# CTRL_MODULE_CORE register map
Vendor: Texas Instruments
Registers are 32-bit, access per field, reset 0x0 unless marked. A register's access mark holds for its fields unless they carry their own. Offsets are as the file gives them; [hi:lo] are bit positions; 'fields as' and 'values as' point back to an identical list.

## CTRL_MODULE_CORE (part 11 of 12)
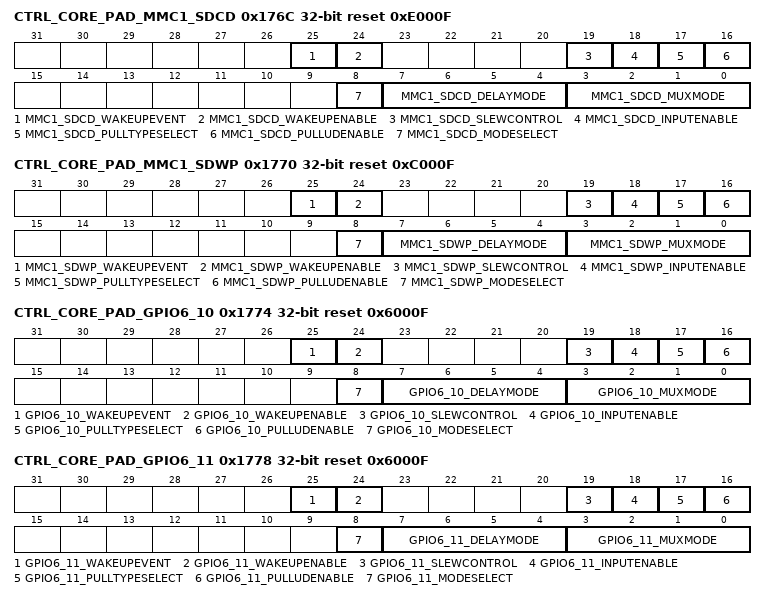
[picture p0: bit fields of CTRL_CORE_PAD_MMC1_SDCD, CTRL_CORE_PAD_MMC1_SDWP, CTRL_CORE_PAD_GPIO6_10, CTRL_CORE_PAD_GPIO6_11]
0x176C CTRL_CORE_PAD_MMC1_SDCD reset 0xE000F
  [25] MMC1_SDCD_WAKEUPEVENT ro
    0=NOWAKEUP (No wakeup event detected); 1=WAKEUP (Wakeup event detected)
  [24] MMC1_SDCD_WAKEUPENABLE rw
    0=DISABLE (Wakeup is disabled); 1=ENABLE (Wakeup is enabled)
  [19] MMC1_SDCD_SLEWCONTROL rw
    0=FAST_SLEW (Fast slew is selected); 1=SLOW_SLEW (Slow slew is selected)
  [18] MMC1_SDCD_INPUTENABLE rw
    0=DISABLE (Receive mode is disabled); 1=ENABLE (Receive mode is enabled)
  [17] MMC1_SDCD_PULLTYPESELECT rw
    0=PULL_DOWN (Pull Down is selected); 1=PULL_UP (Pull Up is selected)
  [16] MMC1_SDCD_PULLUDENABLE rw
    0=ENABLE (Enables weak Pull Up/Down); 1=DISABLE (Disables weak Pull Up/Down)
  [8] MMC1_SDCD_MODESELECT rw — Selects between the Default IO Timing Mode and a Virtual or Manual IO Timing Mode. Refer to the device Data Manual for definition of the required settings for a given mode of operation. When this bit is 0b1, a Virtual IO Timing Mode can be selected via the DELAYMODE field of this register, as described in, Virtual IO Timing Modes. Manual IO Timing Modes are selected via the procedure described in , Manual IO Timing Modes.
    0=MUX_MODE (Default IO Timing Mode is used); 1=DELAY_MODE (A Virtual or Manual IO Timing Mode is used)
  [7:4] MMC1_SDCD_DELAYMODE rw — This bit field selects the Virtual Timing Mode used when the MODESELECT bit is set to 0b1. See, Virtual IO Timing Modes for details.
  [3:0] MMC1_SDCD_MUXMODE rw
    0=MMC1_SDCD; 3=UART6_RXD; 4=I2C4_SDA; 14=GPIO6_27; 15=DRIVER OFF
0x1770 CTRL_CORE_PAD_MMC1_SDWP reset 0xC000F
  [25] MMC1_SDWP_WAKEUPEVENT ro
    values as CTRL_CORE_PAD_MMC1_SDCD.MMC1_SDCD_WAKEUPEVENT
  [24] MMC1_SDWP_WAKEUPENABLE rw
    0=DISABLE (Wakeup is disabled); 1=ENABLE (Wakeup is enabled)
  [19] MMC1_SDWP_SLEWCONTROL rw
    values as CTRL_CORE_PAD_MMC1_SDCD.MMC1_SDCD_SLEWCONTROL
  [18] MMC1_SDWP_INPUTENABLE rw
    values as CTRL_CORE_PAD_MMC1_SDCD.MMC1_SDCD_INPUTENABLE
  [17] MMC1_SDWP_PULLTYPESELECT rw
    values as CTRL_CORE_PAD_MMC1_SDCD.MMC1_SDCD_PULLTYPESELECT
  [16] MMC1_SDWP_PULLUDENABLE rw
    values as CTRL_CORE_PAD_MMC1_SDCD.MMC1_SDCD_PULLUDENABLE
  [8] MMC1_SDWP_MODESELECT rw — Selects between the Default IO Timing Mode and a Virtual or Manual IO Timing Mode. Refer to the device Data Manual for definition of the required settings for a given mode of operation. When this bit is 0b1, a Virtual IO Timing Mode can be selected via the DELAYMODE field of this register, as described in, Virtual IO Timing Modes. Manual IO Timing Modes are selected via the procedure described in , Manual IO Timing Modes.
    values as CTRL_CORE_PAD_MMC1_SDCD.MMC1_SDCD_MODESELECT
  [7:4] MMC1_SDWP_DELAYMODE rw — This bit field selects the Virtual Timing Mode used when the MODESELECT bit is set to 0b1. See, Virtual IO Timing Modes for details.
  [3:0] MMC1_SDWP_MUXMODE rw
    0=MMC1_SDWP; 3=UART6_TXD; 4=I2C4_SCL; 14=GPIO6_28; 15=DRIVER OFF
0x1774 CTRL_CORE_PAD_GPIO6_10 reset 0x6000F
  [25] GPIO6_10_WAKEUPEVENT ro
    values as CTRL_CORE_PAD_MMC1_SDCD.MMC1_SDCD_WAKEUPEVENT
  [24] GPIO6_10_WAKEUPENABLE rw
    0=DISABLE (Wakeup is disabled); 1=ENABLE (Wakeup is enabled)
  [19] GPIO6_10_SLEWCONTROL rw
    values as CTRL_CORE_PAD_MMC1_SDCD.MMC1_SDCD_SLEWCONTROL
  [18] GPIO6_10_INPUTENABLE rw
    values as CTRL_CORE_PAD_MMC1_SDCD.MMC1_SDCD_INPUTENABLE
  [17] GPIO6_10_PULLTYPESELECT rw
    values as CTRL_CORE_PAD_MMC1_SDCD.MMC1_SDCD_PULLTYPESELECT
  [16] GPIO6_10_PULLUDENABLE rw
    values as CTRL_CORE_PAD_MMC1_SDCD.MMC1_SDCD_PULLUDENABLE
  [8] GPIO6_10_MODESELECT rw — Selects between the Default IO Timing Mode and a Virtual or Manual IO Timing Mode. Refer to the device Data Manual for definition of the required settings for a given mode of operation. When this bit is 0b1, a Virtual IO Timing Mode can be selected via the DELAYMODE field of this register, as described in, Virtual IO Timing Modes. Manual IO Timing Modes are selected via the procedure described in , Manual IO Timing Modes.
    values as CTRL_CORE_PAD_MMC1_SDCD.MMC1_SDCD_MODESELECT
  [7:4] GPIO6_10_DELAYMODE rw — This bit field selects the Virtual Timing Mode used when the MODESELECT bit is set to 0b1. See, Virtual IO Timing Modes for details.
  [3:0] GPIO6_10_MUXMODE rw
    0=GPIO6_10; 1=MDIO_MCLK; 2=I2C3_SDA; 4=VIN2B_HSYNC1; 9=VIN5A_CLK0; 10=EHRPWM2A; 11=PR2_MII_MT1_CLK; 12=PR2_PRU0_GPI0; 13=PR2_PRU0_GPO0; 14=GPIO6_10; 15=DRIVER OFF
0x1778 CTRL_CORE_PAD_GPIO6_11 reset 0x6000F
  [25] GPIO6_11_WAKEUPEVENT ro
    values as CTRL_CORE_PAD_MMC1_SDCD.MMC1_SDCD_WAKEUPEVENT
  [24] GPIO6_11_WAKEUPENABLE rw
    0=DISABLE (Wakeup is disabled); 1=ENABLE (Wakeup is enabled)
  [19] GPIO6_11_SLEWCONTROL rw
    values as CTRL_CORE_PAD_MMC1_SDCD.MMC1_SDCD_SLEWCONTROL
  [18] GPIO6_11_INPUTENABLE rw
    values as CTRL_CORE_PAD_MMC1_SDCD.MMC1_SDCD_INPUTENABLE
  [17] GPIO6_11_PULLTYPESELECT rw
    values as CTRL_CORE_PAD_MMC1_SDCD.MMC1_SDCD_PULLTYPESELECT
  [16] GPIO6_11_PULLUDENABLE rw
    values as CTRL_CORE_PAD_MMC1_SDCD.MMC1_SDCD_PULLUDENABLE
  [8] GPIO6_11_MODESELECT rw — Selects between the Default IO Timing Mode and a Virtual or Manual IO Timing Mode. Refer to the device Data Manual for definition of the required settings for a given mode of operation. When this bit is 0b1, a Virtual IO Timing Mode can be selected via the DELAYMODE field of this register, as described in, Virtual IO Timing Modes. Manual IO Timing Modes are selected via the procedure described in , Manual IO Timing Modes.
    values as CTRL_CORE_PAD_MMC1_SDCD.MMC1_SDCD_MODESELECT
  [7:4] GPIO6_11_DELAYMODE rw — This bit field selects the Virtual Timing Mode used when the MODESELECT bit is set to 0b1. See, Virtual IO Timing Modes for details.
  [3:0] GPIO6_11_MUXMODE rw
    0=GPIO6_11; 1=MDIO_D; 2=I2C3_SCL; 4=VIN2B_VSYNC1; 9=VIN5A_DE0; 10=EHRPWM2B; 11=PR2_MII1_TXEN; 12=PR2_PRU0_GPI1; 13=PR2_PRU0_GPO1; 14=GPIO6_11; 15=DRIVER OFF
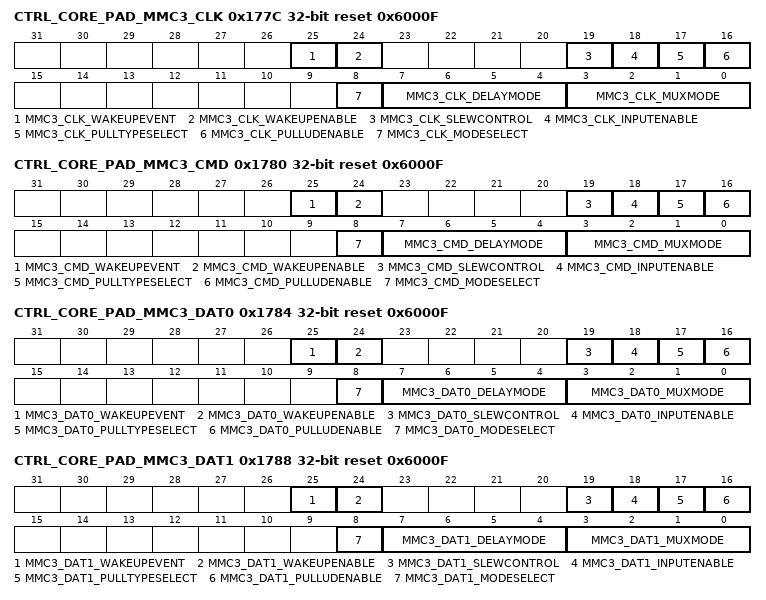
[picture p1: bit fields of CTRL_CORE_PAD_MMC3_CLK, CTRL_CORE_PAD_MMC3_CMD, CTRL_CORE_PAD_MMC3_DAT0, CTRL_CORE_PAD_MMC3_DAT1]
0x177C CTRL_CORE_PAD_MMC3_CLK reset 0x6000F
  [25] MMC3_CLK_WAKEUPEVENT ro
    values as CTRL_CORE_PAD_MMC1_SDCD.MMC1_SDCD_WAKEUPEVENT
  [24] MMC3_CLK_WAKEUPENABLE rw
    0=DISABLE (Wakeup is disabled); 1=ENABLE (Wakeup is enabled)
  [19] MMC3_CLK_SLEWCONTROL rw
    values as CTRL_CORE_PAD_MMC1_SDCD.MMC1_SDCD_SLEWCONTROL
  [18] MMC3_CLK_INPUTENABLE rw
    values as CTRL_CORE_PAD_MMC1_SDCD.MMC1_SDCD_INPUTENABLE
  [17] MMC3_CLK_PULLTYPESELECT rw
    values as CTRL_CORE_PAD_MMC1_SDCD.MMC1_SDCD_PULLTYPESELECT
  [16] MMC3_CLK_PULLUDENABLE rw
    values as CTRL_CORE_PAD_MMC1_SDCD.MMC1_SDCD_PULLUDENABLE
  [8] MMC3_CLK_MODESELECT rw — Selects between the Default IO Timing Mode and a Virtual or Manual IO Timing Mode. Refer to the device Data Manual for definition of the required settings for a given mode of operation. When this bit is 0b1, a Virtual IO Timing Mode can be selected via the DELAYMODE field of this register, as described in, Virtual IO Timing Modes. Manual IO Timing Modes are selected via the procedure described in , Manual IO Timing Modes.
    values as CTRL_CORE_PAD_MMC1_SDCD.MMC1_SDCD_MODESELECT
  [7:4] MMC3_CLK_DELAYMODE rw — This bit field selects the Virtual Timing Mode used when the MODESELECT bit is set to 0b1. See, Virtual IO Timing Modes for details.
  [3:0] MMC3_CLK_MUXMODE rw
    0=MMC3_CLK; 4=VIN2B_D7; 9=VIN5A_D7; 10=EHRPWM2_TRIPZONE_INPUT; 11=PR2_MII1_TXD3; 12=PR2_PRU0_GPI2; 13=PR2_PRU0_GPO2; 14=GPIO6_29; 15=DRIVER OFF
0x1780 CTRL_CORE_PAD_MMC3_CMD reset 0x6000F
  [25] MMC3_CMD_WAKEUPEVENT ro
    values as CTRL_CORE_PAD_MMC1_SDCD.MMC1_SDCD_WAKEUPEVENT
  [24] MMC3_CMD_WAKEUPENABLE rw
    0=DISABLE (Wakeup is disabled); 1=ENABLE (Wakeup is enabled)
  [19] MMC3_CMD_SLEWCONTROL rw
    values as CTRL_CORE_PAD_MMC1_SDCD.MMC1_SDCD_SLEWCONTROL
  [18] MMC3_CMD_INPUTENABLE rw
    values as CTRL_CORE_PAD_MMC1_SDCD.MMC1_SDCD_INPUTENABLE
  [17] MMC3_CMD_PULLTYPESELECT rw
    values as CTRL_CORE_PAD_MMC1_SDCD.MMC1_SDCD_PULLTYPESELECT
  [16] MMC3_CMD_PULLUDENABLE rw
    values as CTRL_CORE_PAD_MMC1_SDCD.MMC1_SDCD_PULLUDENABLE
  [8] MMC3_CMD_MODESELECT rw — Selects between the Default IO Timing Mode and a Virtual or Manual IO Timing Mode. Refer to the device Data Manual for definition of the required settings for a given mode of operation. When this bit is 0b1, a Virtual IO Timing Mode can be selected via the DELAYMODE field of this register, as described in, Virtual IO Timing Modes. Manual IO Timing Modes are selected via the procedure described in , Manual IO Timing Modes.
    values as CTRL_CORE_PAD_MMC1_SDCD.MMC1_SDCD_MODESELECT
  [7:4] MMC3_CMD_DELAYMODE rw — This bit field selects the Virtual Timing Mode used when the MODESELECT bit is set to 0b1. See, Virtual IO Timing Modes for details.
  [3:0] MMC3_CMD_MUXMODE rw
    0=MMC3_CMD; 1=SPI3_SCLK; 4=VIN2B_D6; 9=VIN5A_D6; 10=ECAP2_IN_PWM2_OUT; 11=PR2_MII1_TXD2; 12=PR2_PRU0_GPI3; 13=PR2_PRU0_GPO3; 14=GPIO6_30; 15=DRIVER OFF
0x1784 CTRL_CORE_PAD_MMC3_DAT0 reset 0x6000F
  [25] MMC3_DAT0_WAKEUPEVENT ro
    values as CTRL_CORE_PAD_MMC1_SDCD.MMC1_SDCD_WAKEUPEVENT
  [24] MMC3_DAT0_WAKEUPENABLE rw
    0=DISABLE (Wakeup is disabled); 1=ENABLE (Wakeup is enabled)
  [19] MMC3_DAT0_SLEWCONTROL rw
    values as CTRL_CORE_PAD_MMC1_SDCD.MMC1_SDCD_SLEWCONTROL
  [18] MMC3_DAT0_INPUTENABLE rw
    values as CTRL_CORE_PAD_MMC1_SDCD.MMC1_SDCD_INPUTENABLE
  [17] MMC3_DAT0_PULLTYPESELECT rw
    values as CTRL_CORE_PAD_MMC1_SDCD.MMC1_SDCD_PULLTYPESELECT
  [16] MMC3_DAT0_PULLUDENABLE rw
    values as CTRL_CORE_PAD_MMC1_SDCD.MMC1_SDCD_PULLUDENABLE
  [8] MMC3_DAT0_MODESELECT rw — Selects between the Default IO Timing Mode and a Virtual or Manual IO Timing Mode. Refer to the device Data Manual for definition of the required settings for a given mode of operation. When this bit is 0b1, a Virtual IO Timing Mode can be selected via the DELAYMODE field of this register, as described in, Virtual IO Timing Modes. Manual IO Timing Modes are selected via the procedure described in , Manual IO Timing Modes.
    values as CTRL_CORE_PAD_MMC1_SDCD.MMC1_SDCD_MODESELECT
  [7:4] MMC3_DAT0_DELAYMODE rw — This bit field selects the Virtual Timing Mode used when the MODESELECT bit is set to 0b1. See, Virtual IO Timing Modes for details.
  [3:0] MMC3_DAT0_MUXMODE rw
    0=MMC3_DAT0; 1=SPI3_D1; 2=UART5_RXD; 4=VIN2B_D5; 9=VIN5A_D5; 10=EQEP3A_IN; 11=PR2_MII1_TXD1; 12=PR2_PRU0_GPI4; 13=PR2_PRU0_GPO4; 14=GPIO6_31; 15=DRIVER OFF
0x1788 CTRL_CORE_PAD_MMC3_DAT1 reset 0x6000F
  [25] MMC3_DAT1_WAKEUPEVENT ro
    values as CTRL_CORE_PAD_MMC1_SDCD.MMC1_SDCD_WAKEUPEVENT
  [24] MMC3_DAT1_WAKEUPENABLE rw
    0=DISABLE (Wakeup is disabled); 1=ENABLE (Wakeup is enabled)
  [19] MMC3_DAT1_SLEWCONTROL rw
    values as CTRL_CORE_PAD_MMC1_SDCD.MMC1_SDCD_SLEWCONTROL
  [18] MMC3_DAT1_INPUTENABLE rw
    values as CTRL_CORE_PAD_MMC1_SDCD.MMC1_SDCD_INPUTENABLE
  [17] MMC3_DAT1_PULLTYPESELECT rw
    values as CTRL_CORE_PAD_MMC1_SDCD.MMC1_SDCD_PULLTYPESELECT
  [16] MMC3_DAT1_PULLUDENABLE rw
    values as CTRL_CORE_PAD_MMC1_SDCD.MMC1_SDCD_PULLUDENABLE
  [8] MMC3_DAT1_MODESELECT rw — Selects between the Default IO Timing Mode and a Virtual or Manual IO Timing Mode. Refer to the device Data Manual for definition of the required settings for a given mode of operation. When this bit is 0b1, a Virtual IO Timing Mode can be selected via the DELAYMODE field of this register, as described in, Virtual IO Timing Modes. Manual IO Timing Modes are selected via the procedure described in , Manual IO Timing Modes.
    values as CTRL_CORE_PAD_MMC1_SDCD.MMC1_SDCD_MODESELECT
  [7:4] MMC3_DAT1_DELAYMODE rw — This bit field selects the Virtual Timing Mode used when the MODESELECT bit is set to 0b1. See, Virtual IO Timing Modes for details.
  [3:0] MMC3_DAT1_MUXMODE rw
    0=MMC3_DAT1; 1=SPI3_D0; 2=UART5_TXD; 4=VIN2B_D4; 9=VIN5A_D4; 10=EQEP3B_IN; 11=PR2_MII1_TXD0; 12=PR2_PRU0_GPI5; 13=PR2_PRU0_GPO5; 14=GPIO7_0; 15=DRIVER OFF
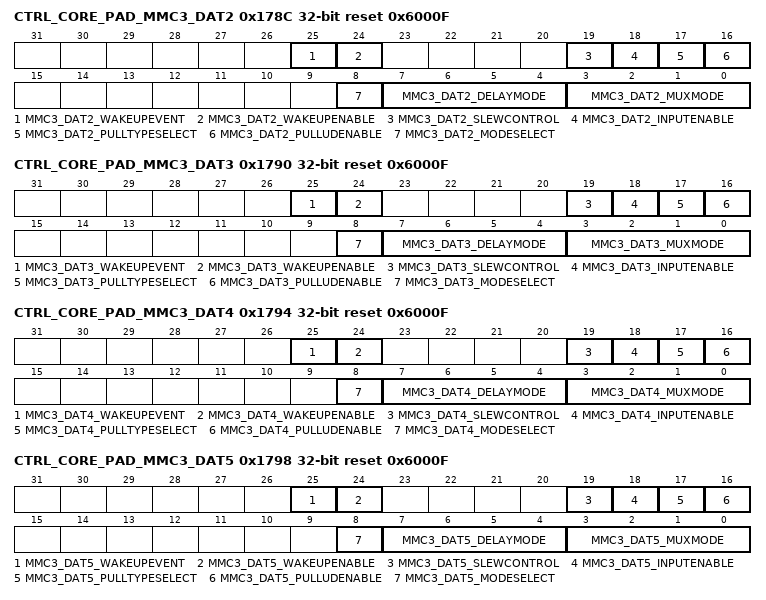
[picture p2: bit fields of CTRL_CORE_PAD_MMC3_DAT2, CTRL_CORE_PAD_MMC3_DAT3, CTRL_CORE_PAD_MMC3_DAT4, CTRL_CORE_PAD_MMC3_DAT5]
0x178C CTRL_CORE_PAD_MMC3_DAT2 reset 0x6000F
  [25] MMC3_DAT2_WAKEUPEVENT ro
    values as CTRL_CORE_PAD_MMC1_SDCD.MMC1_SDCD_WAKEUPEVENT
  [24] MMC3_DAT2_WAKEUPENABLE rw
    0=DISABLE (Wakeup is disabled); 1=ENABLE (Wakeup is enabled)
  [19] MMC3_DAT2_SLEWCONTROL rw
    values as CTRL_CORE_PAD_MMC1_SDCD.MMC1_SDCD_SLEWCONTROL
  [18] MMC3_DAT2_INPUTENABLE rw
    values as CTRL_CORE_PAD_MMC1_SDCD.MMC1_SDCD_INPUTENABLE
  [17] MMC3_DAT2_PULLTYPESELECT rw
    values as CTRL_CORE_PAD_MMC1_SDCD.MMC1_SDCD_PULLTYPESELECT
  [16] MMC3_DAT2_PULLUDENABLE rw
    values as CTRL_CORE_PAD_MMC1_SDCD.MMC1_SDCD_PULLUDENABLE
  [8] MMC3_DAT2_MODESELECT rw — Selects between the Default IO Timing Mode and a Virtual or Manual IO Timing Mode. Refer to the device Data Manual for definition of the required settings for a given mode of operation. When this bit is 0b1, a Virtual IO Timing Mode can be selected via the DELAYMODE field of this register, as described in, Virtual IO Timing Modes. Manual IO Timing Modes are selected via the procedure described in , Manual IO Timing Modes.
    values as CTRL_CORE_PAD_MMC1_SDCD.MMC1_SDCD_MODESELECT
  [7:4] MMC3_DAT2_DELAYMODE rw — This bit field selects the Virtual Timing Mode used when the MODESELECT bit is set to 0b1. See, Virtual IO Timing Modes for details.
  [3:0] MMC3_DAT2_MUXMODE rw
    0=MMC3_DAT2; 1=SPI3_CS0; 2=UART5_CTSN; 4=VIN2B_D3; 9=VIN5A_D3; 10=EQEP3_INDEX; 11=PR2_MII_MR1_CLK; 12=PR2_PRU0_GPI6; 13=PR2_PRU0_GPO6; 14=GPIO7_1; 15=DRIVER OFF
0x1790 CTRL_CORE_PAD_MMC3_DAT3 reset 0x6000F
  [25] MMC3_DAT3_WAKEUPEVENT ro
    values as CTRL_CORE_PAD_MMC1_SDCD.MMC1_SDCD_WAKEUPEVENT
  [24] MMC3_DAT3_WAKEUPENABLE rw
    0=DISABLE (Wakeup is disabled); 1=ENABLE (Wakeup is enabled)
  [19] MMC3_DAT3_SLEWCONTROL rw
    values as CTRL_CORE_PAD_MMC1_SDCD.MMC1_SDCD_SLEWCONTROL
  [18] MMC3_DAT3_INPUTENABLE rw
    values as CTRL_CORE_PAD_MMC1_SDCD.MMC1_SDCD_INPUTENABLE
  [17] MMC3_DAT3_PULLTYPESELECT rw
    values as CTRL_CORE_PAD_MMC1_SDCD.MMC1_SDCD_PULLTYPESELECT
  [16] MMC3_DAT3_PULLUDENABLE rw
    values as CTRL_CORE_PAD_MMC1_SDCD.MMC1_SDCD_PULLUDENABLE
  [8] MMC3_DAT3_MODESELECT rw — Selects between the Default IO Timing Mode and a Virtual or Manual IO Timing Mode. Refer to the device Data Manual for definition of the required settings for a given mode of operation. When this bit is 0b1, a Virtual IO Timing Mode can be selected via the DELAYMODE field of this register, as described in, Virtual IO Timing Modes. Manual IO Timing Modes are selected via the procedure described in , Manual IO Timing Modes.
    values as CTRL_CORE_PAD_MMC1_SDCD.MMC1_SDCD_MODESELECT
  [7:4] MMC3_DAT3_DELAYMODE rw — This bit field selects the Virtual Timing Mode used when the MODESELECT bit is set to 0b1. See, Virtual IO Timing Modes for details.
  [3:0] MMC3_DAT3_MUXMODE rw
    0=MMC3_DAT3; 1=SPI3_CS1; 2=UART5_RTSN; 4=VIN2B_D2; 9=VIN5A_D2; 10=EQEP3_STROBE; 11=PR2_MII1_RXDV; 12=PR2_PRU0_GPI7; 13=PR2_PRU0_GPO7; 14=GPIO7_2; 15=DRIVER OFF
0x1794 CTRL_CORE_PAD_MMC3_DAT4 reset 0x6000F
  [25] MMC3_DAT4_WAKEUPEVENT ro
    values as CTRL_CORE_PAD_MMC1_SDCD.MMC1_SDCD_WAKEUPEVENT
  [24] MMC3_DAT4_WAKEUPENABLE rw
    0=DISABLE (Wakeup is disabled); 1=ENABLE (Wakeup is enabled)
  [19] MMC3_DAT4_SLEWCONTROL rw
    values as CTRL_CORE_PAD_MMC1_SDCD.MMC1_SDCD_SLEWCONTROL
  [18] MMC3_DAT4_INPUTENABLE rw
    values as CTRL_CORE_PAD_MMC1_SDCD.MMC1_SDCD_INPUTENABLE
  [17] MMC3_DAT4_PULLTYPESELECT rw
    values as CTRL_CORE_PAD_MMC1_SDCD.MMC1_SDCD_PULLTYPESELECT
  [16] MMC3_DAT4_PULLUDENABLE rw
    values as CTRL_CORE_PAD_MMC1_SDCD.MMC1_SDCD_PULLUDENABLE
  [8] MMC3_DAT4_MODESELECT rw — Selects between the Default IO Timing Mode and a Virtual or Manual IO Timing Mode. Refer to the device Data Manual for definition of the required settings for a given mode of operation. When this bit is 0b1, a Virtual IO Timing Mode can be selected via the DELAYMODE field of this register, as described in, Virtual IO Timing Modes. Manual IO Timing Modes are selected via the procedure described in , Manual IO Timing Modes.
    values as CTRL_CORE_PAD_MMC1_SDCD.MMC1_SDCD_MODESELECT
  [7:4] MMC3_DAT4_DELAYMODE rw — This bit field selects the Virtual Timing Mode used when the MODESELECT bit is set to 0b1. See, Virtual IO Timing Modes for details.
  [3:0] MMC3_DAT4_MUXMODE rw
    0=MMC3_DAT4; 1=SPI4_SCLK; 2=UART10_RXD; 4=VIN2B_D1; 9=VIN5A_D1; 10=EHRPWM3A; 11=PR2_MII1_RXD3; 12=PR2_PRU0_GPI8; 13=PR2_PRU0_GPO8; 14=GPIO1_22; 15=DRIVER OFF
0x1798 CTRL_CORE_PAD_MMC3_DAT5 reset 0x6000F
  [25] MMC3_DAT5_WAKEUPEVENT ro
    values as CTRL_CORE_PAD_MMC1_SDCD.MMC1_SDCD_WAKEUPEVENT
  [24] MMC3_DAT5_WAKEUPENABLE rw
    0=DISABLE (Wakeup is disabled); 1=ENABLE (Wakeup is enabled)
  [19] MMC3_DAT5_SLEWCONTROL rw
    values as CTRL_CORE_PAD_MMC1_SDCD.MMC1_SDCD_SLEWCONTROL
  [18] MMC3_DAT5_INPUTENABLE rw
    values as CTRL_CORE_PAD_MMC1_SDCD.MMC1_SDCD_INPUTENABLE
  [17] MMC3_DAT5_PULLTYPESELECT rw
    values as CTRL_CORE_PAD_MMC1_SDCD.MMC1_SDCD_PULLTYPESELECT
  [16] MMC3_DAT5_PULLUDENABLE rw
    values as CTRL_CORE_PAD_MMC1_SDCD.MMC1_SDCD_PULLUDENABLE
  [8] MMC3_DAT5_MODESELECT rw — Selects between the Default IO Timing Mode and a Virtual or Manual IO Timing Mode. Refer to the device Data Manual for definition of the required settings for a given mode of operation. When this bit is 0b1, a Virtual IO Timing Mode can be selected via the DELAYMODE field of this register, as described in, Virtual IO Timing Modes. Manual IO Timing Modes are selected via the procedure described in , Manual IO Timing Modes.
    values as CTRL_CORE_PAD_MMC1_SDCD.MMC1_SDCD_MODESELECT
  [7:4] MMC3_DAT5_DELAYMODE rw — This bit field selects the Virtual Timing Mode used when the MODESELECT bit is set to 0b1. See, Virtual IO Timing Modes for details.
  [3:0] MMC3_DAT5_MUXMODE rw
    0=MMC3_DAT5; 1=SPI4_D1; 2=UART10_TXD; 4=VIN2B_D0; 9=VIN5A_D0; 10=EHRPWM3B; 11=PR2_MII1_RXD2; 12=PR2_PRU0_GPI9; 13=PR2_PRU0_GPO9; 14=GPIO1_23; 15=DRIVER OFF
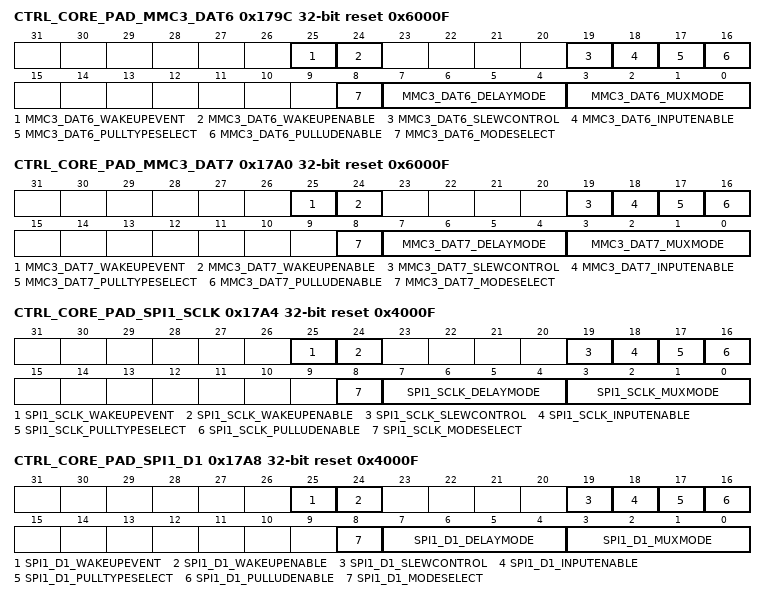
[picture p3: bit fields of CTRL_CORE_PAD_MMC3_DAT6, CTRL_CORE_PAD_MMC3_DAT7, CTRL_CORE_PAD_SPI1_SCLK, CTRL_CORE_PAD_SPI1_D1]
0x179C CTRL_CORE_PAD_MMC3_DAT6 reset 0x6000F
  [25] MMC3_DAT6_WAKEUPEVENT ro
    values as CTRL_CORE_PAD_MMC1_SDCD.MMC1_SDCD_WAKEUPEVENT
  [24] MMC3_DAT6_WAKEUPENABLE rw
    0=DISABLE (Wakeup is disabled); 1=ENABLE (Wakeup is enabled)
  [19] MMC3_DAT6_SLEWCONTROL rw
    values as CTRL_CORE_PAD_MMC1_SDCD.MMC1_SDCD_SLEWCONTROL
  [18] MMC3_DAT6_INPUTENABLE rw
    values as CTRL_CORE_PAD_MMC1_SDCD.MMC1_SDCD_INPUTENABLE
  [17] MMC3_DAT6_PULLTYPESELECT rw
    values as CTRL_CORE_PAD_MMC1_SDCD.MMC1_SDCD_PULLTYPESELECT
  [16] MMC3_DAT6_PULLUDENABLE rw
    values as CTRL_CORE_PAD_MMC1_SDCD.MMC1_SDCD_PULLUDENABLE
  [8] MMC3_DAT6_MODESELECT rw — Selects between the Default IO Timing Mode and a Virtual or Manual IO Timing Mode. Refer to the device Data Manual for definition of the required settings for a given mode of operation. When this bit is 0b1, a Virtual IO Timing Mode can be selected via the DELAYMODE field of this register, as described in, Virtual IO Timing Modes. Manual IO Timing Modes are selected via the procedure described in , Manual IO Timing Modes.
    values as CTRL_CORE_PAD_MMC1_SDCD.MMC1_SDCD_MODESELECT
  [7:4] MMC3_DAT6_DELAYMODE rw — This bit field selects the Virtual Timing Mode used when the MODESELECT bit is set to 0b1. See, Virtual IO Timing Modes for details.
  [3:0] MMC3_DAT6_MUXMODE rw
    0=MMC3_DAT6; 1=SPI4_D0; 2=UART10_CTSN; 4=VIN2B_DE1; 9=VIN5A_HSYNC0; 10=EHRPWM3_TRIPZONE_INPUT; 11=PR2_MII1_RXD1; 12=PR2_PRU0_GPI10; 13=PR2_PRU0_GPO10; 14=GPIO1_24; 15=DRIVER OFF
0x17A0 CTRL_CORE_PAD_MMC3_DAT7 reset 0x6000F
  [25] MMC3_DAT7_WAKEUPEVENT ro
    values as CTRL_CORE_PAD_MMC1_SDCD.MMC1_SDCD_WAKEUPEVENT
  [24] MMC3_DAT7_WAKEUPENABLE rw
    0=DISABLE (Wakeup is disabled); 1=ENABLE (Wakeup is enabled)
  [19] MMC3_DAT7_SLEWCONTROL rw
    values as CTRL_CORE_PAD_MMC1_SDCD.MMC1_SDCD_SLEWCONTROL
  [18] MMC3_DAT7_INPUTENABLE rw
    values as CTRL_CORE_PAD_MMC1_SDCD.MMC1_SDCD_INPUTENABLE
  [17] MMC3_DAT7_PULLTYPESELECT rw
    values as CTRL_CORE_PAD_MMC1_SDCD.MMC1_SDCD_PULLTYPESELECT
  [16] MMC3_DAT7_PULLUDENABLE rw
    values as CTRL_CORE_PAD_MMC1_SDCD.MMC1_SDCD_PULLUDENABLE
  [8] MMC3_DAT7_MODESELECT rw — Selects between the Default IO Timing Mode and a Virtual or Manual IO Timing Mode. Refer to the device Data Manual for definition of the required settings for a given mode of operation. When this bit is 0b1, a Virtual IO Timing Mode can be selected via the DELAYMODE field of this register, as described in, Virtual IO Timing Modes. Manual IO Timing Modes are selected via the procedure described in , Manual IO Timing Modes.
    values as CTRL_CORE_PAD_MMC1_SDCD.MMC1_SDCD_MODESELECT
  [7:4] MMC3_DAT7_DELAYMODE rw — This bit field selects the Virtual Timing Mode used when the MODESELECT bit is set to 0b1. See, Virtual IO Timing Modes for details.
  [3:0] MMC3_DAT7_MUXMODE rw
    0=MMC3_DAT7; 1=SPI4_CS0; 2=UART10_RTSN; 4=VIN2B_CLK1; 9=VIN5A_VSYNC0; 10=ECAP3_IN_PWM3_OUT; 11=PR2_MII1_RXD0; 12=PR2_PRU0_GPI11; 13=PR2_PRU0_GPO11; 14=GPIO1_25; 15=DRIVER OFF
0x17A4 CTRL_CORE_PAD_SPI1_SCLK reset 0x4000F
  [25] SPI1_SCLK_WAKEUPEVENT ro
    values as CTRL_CORE_PAD_MMC1_SDCD.MMC1_SDCD_WAKEUPEVENT
  [24] SPI1_SCLK_WAKEUPENABLE rw
    0=DISABLE (Wakeup is disabled); 1=ENABLE (Wakeup is enabled)
  [19] SPI1_SCLK_SLEWCONTROL rw
    values as CTRL_CORE_PAD_MMC1_SDCD.MMC1_SDCD_SLEWCONTROL
  [18] SPI1_SCLK_INPUTENABLE rw
    values as CTRL_CORE_PAD_MMC1_SDCD.MMC1_SDCD_INPUTENABLE
  [17] SPI1_SCLK_PULLTYPESELECT rw
    values as CTRL_CORE_PAD_MMC1_SDCD.MMC1_SDCD_PULLTYPESELECT
  [16] SPI1_SCLK_PULLUDENABLE rw
    values as CTRL_CORE_PAD_MMC1_SDCD.MMC1_SDCD_PULLUDENABLE
  [8] SPI1_SCLK_MODESELECT rw — Selects between the Default IO Timing Mode and a Virtual or Manual IO Timing Mode. Refer to the device Data Manual for definition of the required settings for a given mode of operation. When this bit is 0b1, a Virtual IO Timing Mode can be selected via the DELAYMODE field of this register, as described in, Virtual IO Timing Modes. Manual IO Timing Modes are selected via the procedure described in , Manual IO Timing Modes.
    values as CTRL_CORE_PAD_MMC1_SDCD.MMC1_SDCD_MODESELECT
  [7:4] SPI1_SCLK_DELAYMODE rw — This bit field selects the Virtual Timing Mode used when the MODESELECT bit is set to 0b1. See, Virtual IO Timing Modes for details.
  [3:0] SPI1_SCLK_MUXMODE rw
    0=SPI1_SCLK; 14=GPIO7_7; 15=DRIVER OFF
0x17A8 CTRL_CORE_PAD_SPI1_D1 reset 0x4000F
  [25] SPI1_D1_WAKEUPEVENT ro
    values as CTRL_CORE_PAD_MMC1_SDCD.MMC1_SDCD_WAKEUPEVENT
  [24] SPI1_D1_WAKEUPENABLE rw
    0=DISABLE (Wakeup is disabled); 1=ENABLE (Wakeup is enabled)
  [19] SPI1_D1_SLEWCONTROL rw
    values as CTRL_CORE_PAD_MMC1_SDCD.MMC1_SDCD_SLEWCONTROL
  [18] SPI1_D1_INPUTENABLE rw
    values as CTRL_CORE_PAD_MMC1_SDCD.MMC1_SDCD_INPUTENABLE
  [17] SPI1_D1_PULLTYPESELECT rw
    values as CTRL_CORE_PAD_MMC1_SDCD.MMC1_SDCD_PULLTYPESELECT
  [16] SPI1_D1_PULLUDENABLE rw
    values as CTRL_CORE_PAD_MMC1_SDCD.MMC1_SDCD_PULLUDENABLE
  [8] SPI1_D1_MODESELECT rw — Selects between the Default IO Timing Mode and a Virtual or Manual IO Timing Mode. Refer to the device Data Manual for definition of the required settings for a given mode of operation. When this bit is 0b1, a Virtual IO Timing Mode can be selected via the DELAYMODE field of this register, as described in, Virtual IO Timing Modes. Manual IO Timing Modes are selected via the procedure described in , Manual IO Timing Modes.
    values as CTRL_CORE_PAD_MMC1_SDCD.MMC1_SDCD_MODESELECT
  [7:4] SPI1_D1_DELAYMODE rw — This bit field selects the Virtual Timing Mode used when the MODESELECT bit is set to 0b1. See, Virtual IO Timing Modes for details.
  [3:0] SPI1_D1_MUXMODE rw
    0=SPI1_D1; 14=GPIO7_8; 15=DRIVER OFF
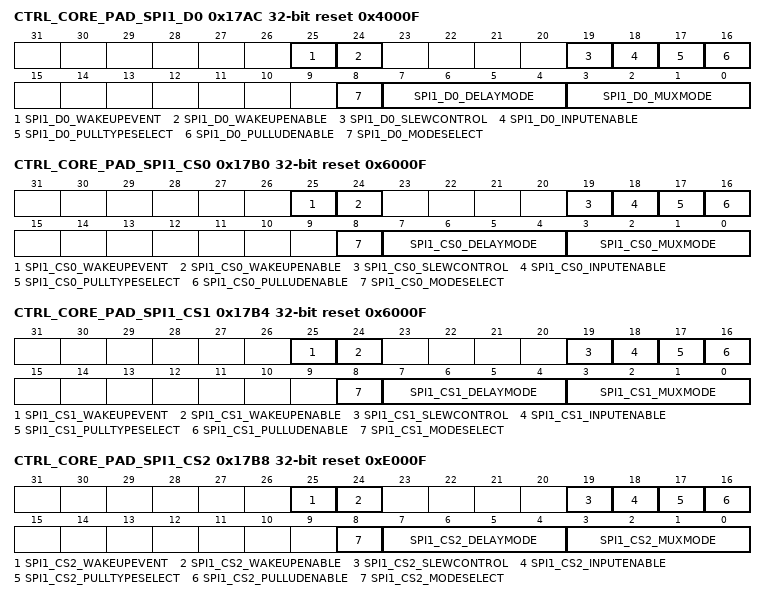
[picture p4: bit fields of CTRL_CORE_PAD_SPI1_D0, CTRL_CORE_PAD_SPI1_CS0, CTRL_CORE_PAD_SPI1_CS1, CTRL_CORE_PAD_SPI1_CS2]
0x17AC CTRL_CORE_PAD_SPI1_D0 reset 0x4000F
  [25] SPI1_D0_WAKEUPEVENT ro
    values as CTRL_CORE_PAD_MMC1_SDCD.MMC1_SDCD_WAKEUPEVENT
  [24] SPI1_D0_WAKEUPENABLE rw
    0=DISABLE (Wakeup is disabled); 1=ENABLE (Wakeup is enabled)
  [19] SPI1_D0_SLEWCONTROL rw
    values as CTRL_CORE_PAD_MMC1_SDCD.MMC1_SDCD_SLEWCONTROL
  [18] SPI1_D0_INPUTENABLE rw
    values as CTRL_CORE_PAD_MMC1_SDCD.MMC1_SDCD_INPUTENABLE
  [17] SPI1_D0_PULLTYPESELECT rw
    values as CTRL_CORE_PAD_MMC1_SDCD.MMC1_SDCD_PULLTYPESELECT
  [16] SPI1_D0_PULLUDENABLE rw
    values as CTRL_CORE_PAD_MMC1_SDCD.MMC1_SDCD_PULLUDENABLE
  [8] SPI1_D0_MODESELECT rw — Selects between the Default IO Timing Mode and a Virtual or Manual IO Timing Mode. Refer to the device Data Manual for definition of the required settings for a given mode of operation. When this bit is 0b1, a Virtual IO Timing Mode can be selected via the DELAYMODE field of this register, as described in, Virtual IO Timing Modes. Manual IO Timing Modes are selected via the procedure described in , Manual IO Timing Modes.
    values as CTRL_CORE_PAD_MMC1_SDCD.MMC1_SDCD_MODESELECT
  [7:4] SPI1_D0_DELAYMODE rw — This bit field selects the Virtual Timing Mode used when the MODESELECT bit is set to 0b1. See, Virtual IO Timing Modes for details.
  [3:0] SPI1_D0_MUXMODE rw
    0=SPI1_D0; 14=GPIO7_9; 15=DRIVER OFF
0x17B0 CTRL_CORE_PAD_SPI1_CS0 reset 0x6000F
  [25] SPI1_CS0_WAKEUPEVENT ro
    values as CTRL_CORE_PAD_MMC1_SDCD.MMC1_SDCD_WAKEUPEVENT
  [24] SPI1_CS0_WAKEUPENABLE rw
    0=DISABLE (Wakeup is disabled); 1=ENABLE (Wakeup is enabled)
  [19] SPI1_CS0_SLEWCONTROL rw
    values as CTRL_CORE_PAD_MMC1_SDCD.MMC1_SDCD_SLEWCONTROL
  [18] SPI1_CS0_INPUTENABLE rw
    values as CTRL_CORE_PAD_MMC1_SDCD.MMC1_SDCD_INPUTENABLE
  [17] SPI1_CS0_PULLTYPESELECT rw
    values as CTRL_CORE_PAD_MMC1_SDCD.MMC1_SDCD_PULLTYPESELECT
  [16] SPI1_CS0_PULLUDENABLE rw
    values as CTRL_CORE_PAD_MMC1_SDCD.MMC1_SDCD_PULLUDENABLE
  [8] SPI1_CS0_MODESELECT rw — Selects between the Default IO Timing Mode and a Virtual or Manual IO Timing Mode. Refer to the device Data Manual for definition of the required settings for a given mode of operation. When this bit is 0b1, a Virtual IO Timing Mode can be selected via the DELAYMODE field of this register, as described in, Virtual IO Timing Modes. Manual IO Timing Modes are selected via the procedure described in , Manual IO Timing Modes.
    values as CTRL_CORE_PAD_MMC1_SDCD.MMC1_SDCD_MODESELECT
  [7:4] SPI1_CS0_DELAYMODE rw — This bit field selects the Virtual Timing Mode used when the MODESELECT bit is set to 0b1. See, Virtual IO Timing Modes for details.
  [3:0] SPI1_CS0_MUXMODE rw
    0=SPI1_CS0; 14=GPIO7_10; 15=DRIVER OFF
0x17B4 CTRL_CORE_PAD_SPI1_CS1 reset 0x6000F
  [25] SPI1_CS1_WAKEUPEVENT ro
    values as CTRL_CORE_PAD_MMC1_SDCD.MMC1_SDCD_WAKEUPEVENT
  [24] SPI1_CS1_WAKEUPENABLE rw
    0=DISABLE (Wakeup is disabled); 1=ENABLE (Wakeup is enabled)
  [19] SPI1_CS1_SLEWCONTROL rw
    values as CTRL_CORE_PAD_MMC1_SDCD.MMC1_SDCD_SLEWCONTROL
  [18] SPI1_CS1_INPUTENABLE rw
    values as CTRL_CORE_PAD_MMC1_SDCD.MMC1_SDCD_INPUTENABLE
  [17] SPI1_CS1_PULLTYPESELECT rw
    values as CTRL_CORE_PAD_MMC1_SDCD.MMC1_SDCD_PULLTYPESELECT
  [16] SPI1_CS1_PULLUDENABLE rw
    values as CTRL_CORE_PAD_MMC1_SDCD.MMC1_SDCD_PULLUDENABLE
  [8] SPI1_CS1_MODESELECT rw — Selects between the Default IO Timing Mode and a Virtual or Manual IO Timing Mode. Refer to the device Data Manual for definition of the required settings for a given mode of operation. When this bit is 0b1, a Virtual IO Timing Mode can be selected via the DELAYMODE field of this register, as described in, Virtual IO Timing Modes. Manual IO Timing Modes are selected via the procedure described in , Manual IO Timing Modes.
    values as CTRL_CORE_PAD_MMC1_SDCD.MMC1_SDCD_MODESELECT
  [7:4] SPI1_CS1_DELAYMODE rw — This bit field selects the Virtual Timing Mode used when the MODESELECT bit is set to 0b1. See, Virtual IO Timing Modes for details.
  [3:0] SPI1_CS1_MUXMODE rw
    0=SPI1_CS1; 2=SATA1_LED; 3=SPI2_CS1; 14=GPIO7_11; 15=DRIVER OFF
0x17B8 CTRL_CORE_PAD_SPI1_CS2 reset 0xE000F
  [25] SPI1_CS2_WAKEUPEVENT ro
    values as CTRL_CORE_PAD_MMC1_SDCD.MMC1_SDCD_WAKEUPEVENT
  [24] SPI1_CS2_WAKEUPENABLE rw
    0=DISABLE (Wakeup is disabled); 1=ENABLE (Wakeup is enabled)
  [19] SPI1_CS2_SLEWCONTROL rw
    values as CTRL_CORE_PAD_MMC1_SDCD.MMC1_SDCD_SLEWCONTROL
  [18] SPI1_CS2_INPUTENABLE rw
    values as CTRL_CORE_PAD_MMC1_SDCD.MMC1_SDCD_INPUTENABLE
  [17] SPI1_CS2_PULLTYPESELECT rw
    values as CTRL_CORE_PAD_MMC1_SDCD.MMC1_SDCD_PULLTYPESELECT
  [16] SPI1_CS2_PULLUDENABLE rw
    values as CTRL_CORE_PAD_MMC1_SDCD.MMC1_SDCD_PULLUDENABLE
  [8] SPI1_CS2_MODESELECT rw — Selects between the Default IO Timing Mode and a Virtual or Manual IO Timing Mode. Refer to the device Data Manual for definition of the required settings for a given mode of operation. When this bit is 0b1, a Virtual IO Timing Mode can be selected via the DELAYMODE field of this register, as described in, Virtual IO Timing Modes. Manual IO Timing Modes are selected via the procedure described in , Manual IO Timing Modes.
    values as CTRL_CORE_PAD_MMC1_SDCD.MMC1_SDCD_MODESELECT
  [7:4] SPI1_CS2_DELAYMODE rw — This bit field selects the Virtual Timing Mode used when the MODESELECT bit is set to 0b1. See, Virtual IO Timing Modes for details.
  [3:0] SPI1_CS2_MUXMODE rw
    0=SPI1_CS2; 1=UART4_RXD; 2=MMC3_SDCD; 3=SPI2_CS2; 4=DCAN2_TX; 5=MDIO_MCLK; 6=HDMI1_HPD; 14=GPIO7_12; 15=DRIVER OFF
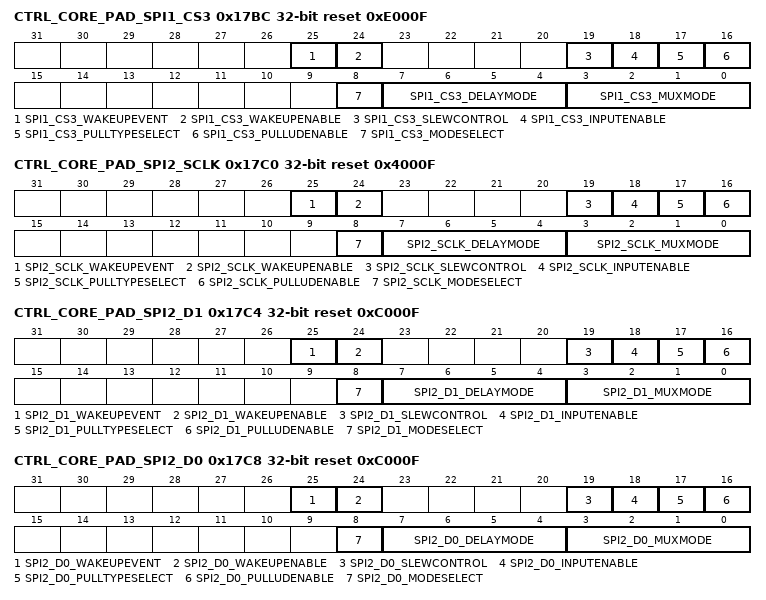
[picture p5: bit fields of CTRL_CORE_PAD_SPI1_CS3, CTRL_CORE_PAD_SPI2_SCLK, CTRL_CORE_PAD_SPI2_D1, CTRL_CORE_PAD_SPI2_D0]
0x17BC CTRL_CORE_PAD_SPI1_CS3 reset 0xE000F
  [25] SPI1_CS3_WAKEUPEVENT ro
    values as CTRL_CORE_PAD_MMC1_SDCD.MMC1_SDCD_WAKEUPEVENT
  [24] SPI1_CS3_WAKEUPENABLE rw
    0=DISABLE (Wakeup is disabled); 1=ENABLE (Wakeup is enabled)
  [19] SPI1_CS3_SLEWCONTROL rw
    values as CTRL_CORE_PAD_MMC1_SDCD.MMC1_SDCD_SLEWCONTROL
  [18] SPI1_CS3_INPUTENABLE rw
    values as CTRL_CORE_PAD_MMC1_SDCD.MMC1_SDCD_INPUTENABLE
  [17] SPI1_CS3_PULLTYPESELECT rw
    values as CTRL_CORE_PAD_MMC1_SDCD.MMC1_SDCD_PULLTYPESELECT
  [16] SPI1_CS3_PULLUDENABLE rw
    values as CTRL_CORE_PAD_MMC1_SDCD.MMC1_SDCD_PULLUDENABLE
  [8] SPI1_CS3_MODESELECT rw — Selects between the Default IO Timing Mode and a Virtual or Manual IO Timing Mode. Refer to the device Data Manual for definition of the required settings for a given mode of operation. When this bit is 0b1, a Virtual IO Timing Mode can be selected via the DELAYMODE field of this register, as described in, Virtual IO Timing Modes. Manual IO Timing Modes are selected via the procedure described in , Manual IO Timing Modes.
    values as CTRL_CORE_PAD_MMC1_SDCD.MMC1_SDCD_MODESELECT
  [7:4] SPI1_CS3_DELAYMODE rw — This bit field selects the Virtual Timing Mode used when the MODESELECT bit is set to 0b1. See, Virtual IO Timing Modes for details.
  [3:0] SPI1_CS3_MUXMODE rw
    0=SPI1_CS3; 1=UART4_TXD; 2=MMC3_SDWP; 3=SPI2_CS3; 4=DCAN2_RX; 5=MDIO_D; 6=HDMI1_CEC; 14=GPIO7_13; 15=DRIVER OFF
0x17C0 CTRL_CORE_PAD_SPI2_SCLK reset 0x4000F
  [25] SPI2_SCLK_WAKEUPEVENT ro
    values as CTRL_CORE_PAD_MMC1_SDCD.MMC1_SDCD_WAKEUPEVENT
  [24] SPI2_SCLK_WAKEUPENABLE rw
    0=DISABLE (Wakeup is disabled); 1=ENABLE (Wakeup is enabled)
  [19] SPI2_SCLK_SLEWCONTROL rw
    values as CTRL_CORE_PAD_MMC1_SDCD.MMC1_SDCD_SLEWCONTROL
  [18] SPI2_SCLK_INPUTENABLE rw
    values as CTRL_CORE_PAD_MMC1_SDCD.MMC1_SDCD_INPUTENABLE
  [17] SPI2_SCLK_PULLTYPESELECT rw
    values as CTRL_CORE_PAD_MMC1_SDCD.MMC1_SDCD_PULLTYPESELECT
  [16] SPI2_SCLK_PULLUDENABLE rw
    values as CTRL_CORE_PAD_MMC1_SDCD.MMC1_SDCD_PULLUDENABLE
  [8] SPI2_SCLK_MODESELECT rw — Selects between the Default IO Timing Mode and a Virtual or Manual IO Timing Mode. Refer to the device Data Manual for definition of the required settings for a given mode of operation. When this bit is 0b1, a Virtual IO Timing Mode can be selected via the DELAYMODE field of this register, as described in, Virtual IO Timing Modes. Manual IO Timing Modes are selected via the procedure described in , Manual IO Timing Modes.
    values as CTRL_CORE_PAD_MMC1_SDCD.MMC1_SDCD_MODESELECT
  [7:4] SPI2_SCLK_DELAYMODE rw — This bit field selects the Virtual Timing Mode used when the MODESELECT bit is set to 0b1. See, Virtual IO Timing Modes for details.
  [3:0] SPI2_SCLK_MUXMODE rw
    0=SPI2_SCLK; 1=UART3_RXD; 14=GPIO7_14; 15=DRIVER OFF
0x17C4 CTRL_CORE_PAD_SPI2_D1 reset 0xC000F
  [25] SPI2_D1_WAKEUPEVENT ro
    values as CTRL_CORE_PAD_MMC1_SDCD.MMC1_SDCD_WAKEUPEVENT
  [24] SPI2_D1_WAKEUPENABLE rw
    0=DISABLE (Wakeup is disabled); 1=ENABLE (Wakeup is enabled)
  [19] SPI2_D1_SLEWCONTROL rw
    values as CTRL_CORE_PAD_MMC1_SDCD.MMC1_SDCD_SLEWCONTROL
  [18] SPI2_D1_INPUTENABLE rw
    values as CTRL_CORE_PAD_MMC1_SDCD.MMC1_SDCD_INPUTENABLE
  [17] SPI2_D1_PULLTYPESELECT rw
    values as CTRL_CORE_PAD_MMC1_SDCD.MMC1_SDCD_PULLTYPESELECT
  [16] SPI2_D1_PULLUDENABLE rw
    values as CTRL_CORE_PAD_MMC1_SDCD.MMC1_SDCD_PULLUDENABLE
  [8] SPI2_D1_MODESELECT rw — Selects between the Default IO Timing Mode and a Virtual or Manual IO Timing Mode. Refer to the device Data Manual for definition of the required settings for a given mode of operation. When this bit is 0b1, a Virtual IO Timing Mode can be selected via the DELAYMODE field of this register, as described in, Virtual IO Timing Modes. Manual IO Timing Modes are selected via the procedure described in , Manual IO Timing Modes.
    values as CTRL_CORE_PAD_MMC1_SDCD.MMC1_SDCD_MODESELECT
  [7:4] SPI2_D1_DELAYMODE rw — This bit field selects the Virtual Timing Mode used when the MODESELECT bit is set to 0b1. See, Virtual IO Timing Modes for details.
  [3:0] SPI2_D1_MUXMODE rw
    0=SPI2_D1; 1=UART3_TXD; 14=GPIO7_15; 15=DRIVER OFF
0x17C8 CTRL_CORE_PAD_SPI2_D0 reset 0xC000F
  [25] SPI2_D0_WAKEUPEVENT ro
    values as CTRL_CORE_PAD_MMC1_SDCD.MMC1_SDCD_WAKEUPEVENT
  [24] SPI2_D0_WAKEUPENABLE rw
    0=DISABLE (Wakeup is disabled); 1=ENABLE (Wakeup is enabled)
  [19] SPI2_D0_SLEWCONTROL rw
    values as CTRL_CORE_PAD_MMC1_SDCD.MMC1_SDCD_SLEWCONTROL
  [18] SPI2_D0_INPUTENABLE rw
    values as CTRL_CORE_PAD_MMC1_SDCD.MMC1_SDCD_INPUTENABLE
  [17] SPI2_D0_PULLTYPESELECT rw
    values as CTRL_CORE_PAD_MMC1_SDCD.MMC1_SDCD_PULLTYPESELECT
  [16] SPI2_D0_PULLUDENABLE rw
    values as CTRL_CORE_PAD_MMC1_SDCD.MMC1_SDCD_PULLUDENABLE
  [8] SPI2_D0_MODESELECT rw — Selects between the Default IO Timing Mode and a Virtual or Manual IO Timing Mode. Refer to the device Data Manual for definition of the required settings for a given mode of operation. When this bit is 0b1, a Virtual IO Timing Mode can be selected via the DELAYMODE field of this register, as described in, Virtual IO Timing Modes. Manual IO Timing Modes are selected via the procedure described in , Manual IO Timing Modes.
    values as CTRL_CORE_PAD_MMC1_SDCD.MMC1_SDCD_MODESELECT
  [7:4] SPI2_D0_DELAYMODE rw — This bit field selects the Virtual Timing Mode used when the MODESELECT bit is set to 0b1. See, Virtual IO Timing Modes for details.
  [3:0] SPI2_D0_MUXMODE rw
    0=SPI2_D0; 1=UART3_CTSN; 2=UART5_RXD; 14=GPIO7_16; 15=DRIVER OFF
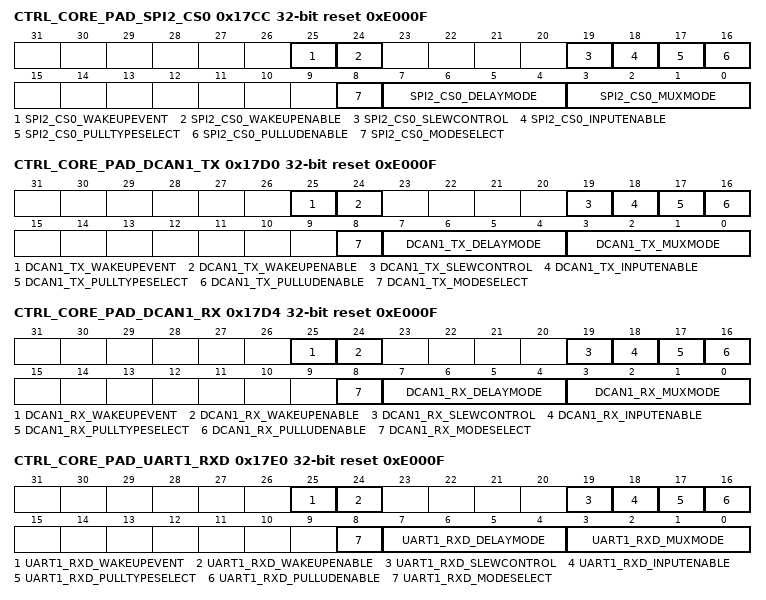
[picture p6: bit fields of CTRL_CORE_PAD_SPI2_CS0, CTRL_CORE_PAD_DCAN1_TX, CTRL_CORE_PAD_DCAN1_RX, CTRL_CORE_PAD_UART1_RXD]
0x17CC CTRL_CORE_PAD_SPI2_CS0 reset 0xE000F
  [25] SPI2_CS0_WAKEUPEVENT ro
    values as CTRL_CORE_PAD_MMC1_SDCD.MMC1_SDCD_WAKEUPEVENT
  [24] SPI2_CS0_WAKEUPENABLE rw
    0=DISABLE (Wakeup is disabled); 1=ENABLE (Wakeup is enabled)
  [19] SPI2_CS0_SLEWCONTROL rw
    values as CTRL_CORE_PAD_MMC1_SDCD.MMC1_SDCD_SLEWCONTROL
  [18] SPI2_CS0_INPUTENABLE rw
    values as CTRL_CORE_PAD_MMC1_SDCD.MMC1_SDCD_INPUTENABLE
  [17] SPI2_CS0_PULLTYPESELECT rw
    values as CTRL_CORE_PAD_MMC1_SDCD.MMC1_SDCD_PULLTYPESELECT
  [16] SPI2_CS0_PULLUDENABLE rw
    values as CTRL_CORE_PAD_MMC1_SDCD.MMC1_SDCD_PULLUDENABLE
  [8] SPI2_CS0_MODESELECT rw — Selects between the Default IO Timing Mode and a Virtual or Manual IO Timing Mode. Refer to the device Data Manual for definition of the required settings for a given mode of operation. When this bit is 0b1, a Virtual IO Timing Mode can be selected via the DELAYMODE field of this register, as described in, Virtual IO Timing Modes. Manual IO Timing Modes are selected via the procedure described in , Manual IO Timing Modes.
    values as CTRL_CORE_PAD_MMC1_SDCD.MMC1_SDCD_MODESELECT
  [7:4] SPI2_CS0_DELAYMODE rw — This bit field selects the Virtual Timing Mode used when the MODESELECT bit is set to 0b1. See, Virtual IO Timing Modes for details.
  [3:0] SPI2_CS0_MUXMODE rw
    0=SPI2_CS0; 1=UART3_RTSN; 2=UART5_TXD; 14=GPIO7_17; 15=DRIVER OFF
0x17D0 CTRL_CORE_PAD_DCAN1_TX reset 0xE000F
  [25] DCAN1_TX_WAKEUPEVENT ro
    values as CTRL_CORE_PAD_MMC1_SDCD.MMC1_SDCD_WAKEUPEVENT
  [24] DCAN1_TX_WAKEUPENABLE rw
    0=DISABLE (Wakeup is disabled); 1=ENABLE (Wakeup is enabled)
  [19] DCAN1_TX_SLEWCONTROL rw
    values as CTRL_CORE_PAD_MMC1_SDCD.MMC1_SDCD_SLEWCONTROL
  [18] DCAN1_TX_INPUTENABLE rw
    values as CTRL_CORE_PAD_MMC1_SDCD.MMC1_SDCD_INPUTENABLE
  [17] DCAN1_TX_PULLTYPESELECT rw
    values as CTRL_CORE_PAD_MMC1_SDCD.MMC1_SDCD_PULLTYPESELECT
  [16] DCAN1_TX_PULLUDENABLE rw
    values as CTRL_CORE_PAD_MMC1_SDCD.MMC1_SDCD_PULLUDENABLE
  [8] DCAN1_TX_MODESELECT rw — Selects between the Default IO Timing Mode and a Virtual or Manual IO Timing Mode. Refer to the device Data Manual for definition of the required settings for a given mode of operation. When this bit is 0b1, a Virtual IO Timing Mode can be selected via the DELAYMODE field of this register, as described in, Virtual IO Timing Modes. Manual IO Timing Modes are selected via the procedure described in , Manual IO Timing Modes.
    values as CTRL_CORE_PAD_MMC1_SDCD.MMC1_SDCD_MODESELECT
  [7:4] DCAN1_TX_DELAYMODE rw — This bit field selects the Virtual Timing Mode used when the MODESELECT bit is set to 0b1. See, Virtual IO Timing Modes for details.
  [3:0] DCAN1_TX_MUXMODE rw
    0=DCAN1_TX; 2=UART8_RXD; 3=MMC2_SDCD; 6=HDMI1_HPD; 14=GPIO1_14; 15=DRIVER OFF
0x17D4 CTRL_CORE_PAD_DCAN1_RX reset 0xE000F
  [25] DCAN1_RX_WAKEUPEVENT ro
    values as CTRL_CORE_PAD_MMC1_SDCD.MMC1_SDCD_WAKEUPEVENT
  [24] DCAN1_RX_WAKEUPENABLE rw
    0=DISABLE (Wakeup is disabled); 1=ENABLE (Wakeup is enabled)
  [19] DCAN1_RX_SLEWCONTROL rw
    values as CTRL_CORE_PAD_MMC1_SDCD.MMC1_SDCD_SLEWCONTROL
  [18] DCAN1_RX_INPUTENABLE rw
    values as CTRL_CORE_PAD_MMC1_SDCD.MMC1_SDCD_INPUTENABLE
  [17] DCAN1_RX_PULLTYPESELECT rw
    values as CTRL_CORE_PAD_MMC1_SDCD.MMC1_SDCD_PULLTYPESELECT
  [16] DCAN1_RX_PULLUDENABLE rw
    values as CTRL_CORE_PAD_MMC1_SDCD.MMC1_SDCD_PULLUDENABLE
  [8] DCAN1_RX_MODESELECT rw — Selects between the Default IO Timing Mode and a Virtual or Manual IO Timing Mode. Refer to the device Data Manual for definition of the required settings for a given mode of operation. When this bit is 0b1, a Virtual IO Timing Mode can be selected via the DELAYMODE field of this register, as described in, Virtual IO Timing Modes. Manual IO Timing Modes are selected via the procedure described in , Manual IO Timing Modes.
    values as CTRL_CORE_PAD_MMC1_SDCD.MMC1_SDCD_MODESELECT
  [7:4] DCAN1_RX_DELAYMODE rw — This bit field selects the Virtual Timing Mode used when the MODESELECT bit is set to 0b1. See, Virtual IO Timing Modes for details.
  [3:0] DCAN1_RX_MUXMODE rw
    0=DCAN1_RX; 2=UART8_TXD; 3=MMC2_SDWP; 4=SATA1_LED; 6=HDMI1_CEC; 14=GPIO1_15; 15=DRIVER OFF
0x17E0 CTRL_CORE_PAD_UART1_RXD reset 0xE000F
  [25] UART1_RXD_WAKEUPEVENT ro
    values as CTRL_CORE_PAD_MMC1_SDCD.MMC1_SDCD_WAKEUPEVENT
  [24] UART1_RXD_WAKEUPENABLE rw
    0=DISABLE (Wakeup is disabled); 1=ENABLE (Wakeup is enabled)
  [19] UART1_RXD_SLEWCONTROL rw
    values as CTRL_CORE_PAD_MMC1_SDCD.MMC1_SDCD_SLEWCONTROL
  [18] UART1_RXD_INPUTENABLE rw
    values as CTRL_CORE_PAD_MMC1_SDCD.MMC1_SDCD_INPUTENABLE
  [17] UART1_RXD_PULLTYPESELECT rw
    values as CTRL_CORE_PAD_MMC1_SDCD.MMC1_SDCD_PULLTYPESELECT
  [16] UART1_RXD_PULLUDENABLE rw
    values as CTRL_CORE_PAD_MMC1_SDCD.MMC1_SDCD_PULLUDENABLE
  [8] UART1_RXD_MODESELECT rw — Selects between the Default IO Timing Mode and a Virtual or Manual IO Timing Mode. Refer to the device Data Manual for definition of the required settings for a given mode of operation. When this bit is 0b1, a Virtual IO Timing Mode can be selected via the DELAYMODE field of this register, as described in, Virtual IO Timing Modes. Manual IO Timing Modes are selected via the procedure described in , Manual IO Timing Modes.
    values as CTRL_CORE_PAD_MMC1_SDCD.MMC1_SDCD_MODESELECT
  [7:4] UART1_RXD_DELAYMODE rw — This bit field selects the Virtual Timing Mode used when the MODESELECT bit is set to 0b1. See, Virtual IO Timing Modes for details.
  [3:0] UART1_RXD_MUXMODE rw
    0=UART1_RXD; 3=MMC4_SDCD; 14=GPIO7_22; 15=DRIVER OFF
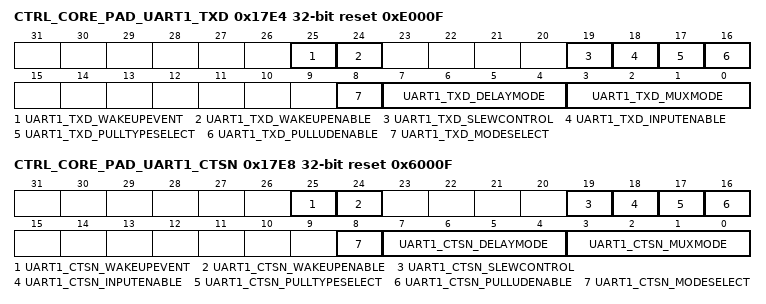
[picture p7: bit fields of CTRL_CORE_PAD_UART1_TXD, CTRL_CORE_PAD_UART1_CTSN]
0x17E4 CTRL_CORE_PAD_UART1_TXD reset 0xE000F
  [25] UART1_TXD_WAKEUPEVENT ro
    values as CTRL_CORE_PAD_MMC1_SDCD.MMC1_SDCD_WAKEUPEVENT
  [24] UART1_TXD_WAKEUPENABLE rw
    0=DISABLE (Wakeup is disabled); 1=ENABLE (Wakeup is enabled)
  [19] UART1_TXD_SLEWCONTROL rw
    values as CTRL_CORE_PAD_MMC1_SDCD.MMC1_SDCD_SLEWCONTROL
  [18] UART1_TXD_INPUTENABLE rw
    values as CTRL_CORE_PAD_MMC1_SDCD.MMC1_SDCD_INPUTENABLE
  [17] UART1_TXD_PULLTYPESELECT rw
    values as CTRL_CORE_PAD_MMC1_SDCD.MMC1_SDCD_PULLTYPESELECT
  [16] UART1_TXD_PULLUDENABLE rw
    values as CTRL_CORE_PAD_MMC1_SDCD.MMC1_SDCD_PULLUDENABLE
  [8] UART1_TXD_MODESELECT rw — Selects between the Default IO Timing Mode and a Virtual or Manual IO Timing Mode. Refer to the device Data Manual for definition of the required settings for a given mode of operation. When this bit is 0b1, a Virtual IO Timing Mode can be selected via the DELAYMODE field of this register, as described in, Virtual IO Timing Modes. Manual IO Timing Modes are selected via the procedure described in , Manual IO Timing Modes.
    values as CTRL_CORE_PAD_MMC1_SDCD.MMC1_SDCD_MODESELECT
  [7:4] UART1_TXD_DELAYMODE rw — This bit field selects the Virtual Timing Mode used when the MODESELECT bit is set to 0b1. See, Virtual IO Timing Modes for details.
  [3:0] UART1_TXD_MUXMODE rw
    0=UART1_TXD; 3=MMC4_SDWP; 14=GPIO7_23; 15=DRIVER OFF
0x17E8 CTRL_CORE_PAD_UART1_CTSN reset 0x6000F
  [25] UART1_CTSN_WAKEUPEVENT ro
    values as CTRL_CORE_PAD_MMC1_SDCD.MMC1_SDCD_WAKEUPEVENT
  [24] UART1_CTSN_WAKEUPENABLE rw
    0=DISABLE (Wakeup is disabled); 1=ENABLE (Wakeup is enabled)
  [19] UART1_CTSN_SLEWCONTROL rw
    values as CTRL_CORE_PAD_MMC1_SDCD.MMC1_SDCD_SLEWCONTROL
  [18] UART1_CTSN_INPUTENABLE rw
    values as CTRL_CORE_PAD_MMC1_SDCD.MMC1_SDCD_INPUTENABLE
  [17] UART1_CTSN_PULLTYPESELECT rw
    values as CTRL_CORE_PAD_MMC1_SDCD.MMC1_SDCD_PULLTYPESELECT
  [16] UART1_CTSN_PULLUDENABLE rw
    values as CTRL_CORE_PAD_MMC1_SDCD.MMC1_SDCD_PULLUDENABLE
  [8] UART1_CTSN_MODESELECT rw — Selects between the Default IO Timing Mode and a Virtual or Manual IO Timing Mode. Refer to the device Data Manual for definition of the required settings for a given mode of operation. When this bit is 0b1, a Virtual IO Timing Mode can be selected via the DELAYMODE field of this register, as described in, Virtual IO Timing Modes. Manual IO Timing Modes are selected via the procedure described in , Manual IO Timing Modes.
    values as CTRL_CORE_PAD_MMC1_SDCD.MMC1_SDCD_MODESELECT
  [7:4] UART1_CTSN_DELAYMODE rw — This bit field selects the Virtual Timing Mode used when the MODESELECT bit is set to 0b1. See, Virtual IO Timing Modes for details.
  [3:0] UART1_CTSN_MUXMODE rw
    0=UART1_CTSN; 2=UART9_RXD; 3=MMC4_CLK; 14=GPIO7_24; 15=DRIVER OFF
